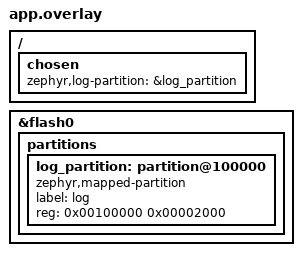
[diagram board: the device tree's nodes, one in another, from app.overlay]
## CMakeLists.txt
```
# Copyright The Zephyr Project Contributors
# SPDX-License-Identifier: Apache-2.0

cmake_minimum_required(VERSION 3.20.0)
find_package(Zephyr REQUIRED HINTS $ENV{ZEPHYR_BASE})
project(log_backend_flash)

# The backend is built as part of Zephyr, not of the application, so the header
# holding the build id has to be on Zephyr's include path.
zephyr_include_directories(src)

target_sources(app PRIVATE src/main.c)
```

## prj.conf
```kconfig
CONFIG_ZTEST=y
CONFIG_ASSERT=y
CONFIG_TEST_LOGGING_DEFAULTS=n

CONFIG_FLASH=y
CONFIG_FLASH_SIMULATOR=y
# The backend only supports memory that does not need an explicit erase, so the
# simulator has to behave like RRAM rather than like NOR.
CONFIG_FLASH_SIMULATOR_EXPLICIT_ERASE=n

CONFIG_LOG=y
CONFIG_LOG_MODE_DEFERRED=y
CONFIG_LOG_PROCESS_THREAD=y
CONFIG_LOG_BACKEND_FLASH=y
CONFIG_LOG_BACKEND_UART=n
CONFIG_LOG_BACKEND_NATIVE_POSIX=n
CONFIG_LOG_PRINTK=n

# Only the test module logs, so that the record counts the test asserts on are
# not disturbed by messages from the rest of the system.
CONFIG_LOG_MAX_LEVEL=4
CONFIG_LOG_DEFAULT_LEVEL=0

CONFIG_LOG_BACKEND_FLASH_BUILD_ID="TEST_BUILD_ID"
CONFIG_LOG_BACKEND_FLASH_BUILD_ID_HEADER="test_build_id.h"
```

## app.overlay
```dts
/*
 * Copyright The Zephyr Project Contributors
 *
 * SPDX-License-Identifier: Apache-2.0
 */

/ {
	chosen {
		zephyr,log-partition = &log_partition;
	};
};

/* The area above 0x100000 is not claimed by any partition on native_sim. */
&flash0 {
	partitions {
		log_partition: partition@100000 {
			compatible = "zephyr,mapped-partition";
			label = "log";
			reg = <0x00100000 0x00002000>;
		};
	};
};
```

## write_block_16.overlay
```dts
/*
 * Copyright The Zephyr Project Contributors
 *
 * SPDX-License-Identifier: Apache-2.0
 */

/*
 * A write block larger than one byte is the interesting case: records do not
 * start on a block boundary, so the backend has to buffer the tail of the
 * partially filled block and rewrite it when the next record arrives. 16 bytes
 * is what the nRF RRAM controller uses.
 */
&flash0 {
	write-block-size = <16>;
};
```

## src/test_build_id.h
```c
/*
 * Copyright The Zephyr Project Contributors
 *
 * SPDX-License-Identifier: Apache-2.0
 */

#ifndef TEST_BUILD_ID_H
#define TEST_BUILD_ID_H

/*
 * What CONFIG_LOG_BACKEND_FLASH_BUILD_ID evaluates to in this test, reached
 * through CONFIG_LOG_BACKEND_FLASH_BUILD_ID_HEADER the same way an application
 * would reach its own version string.
 */
#define TEST_BUILD_ID "log_backend_flash test build"

/** A build id that is not the one the running firmware carries. */
#define TEST_FOREIGN_BUILD_ID "some other firmware"

#endif /* TEST_BUILD_ID_H */
```
